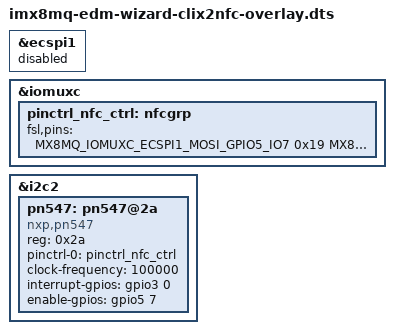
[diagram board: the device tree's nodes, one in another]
/dts-v1/;
/plugin/;

#include "../imx8mq-pinfunc.h"
#include <dt-bindings/clock/imx8mq-clock.h>
#include <dt-bindings/interrupt-controller/irq.h>
#include <dt-bindings/gpio/gpio.h>

/ {
	fragment@0 {
		target = <&ecspi1>;
		__overlay__ {
			status = "disabled";
		};
	};

	fragment@1 {
		target = <&iomuxc>;
		__overlay__ {
			pinctrl-names = "default";

			pinctrl_nfc_ctrl: nfcgrp {
				fsl,pins = <
					MX8MQ_IOMUXC_ECSPI1_MOSI_GPIO5_IO7	0x19	/* PIN_ENABLE */
					MX8MQ_IOMUXC_NAND_ALE_GPIO3_IO0		0x19	/* PIN_INT */
				>;
			};
		};
	};

	fragment@2 {
		target = <&i2c2>;
		__overlay__ {
			#address-cells = <1>;
			#size-cells = <0>;
			status = "okay";
			pn547: pn547@2a {
				compatible = "nxp,pn547";
				reg = <0x2a>;
				pinctrl-names = "default";
				pinctrl-0 = <&pinctrl_nfc_ctrl>;
				clock-frequency = <100000>;
				interrupt-gpios = <&gpio3 0 0>;
				enable-gpios = <&gpio5 7 0>;
				status = "okay";
			};
		};
	};
};
